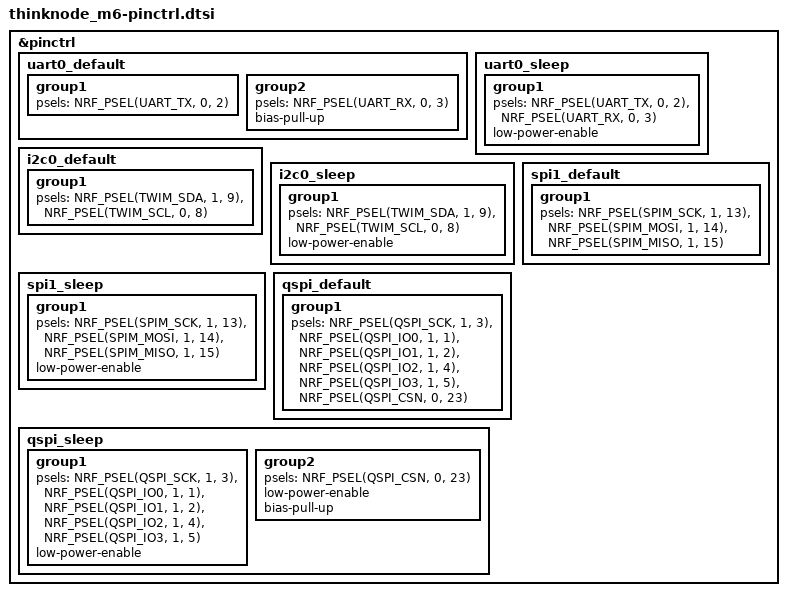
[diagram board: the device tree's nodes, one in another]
/*
 * Elecrow ThinkNode M6 - Pin Control
 * Copyright (c) 2025 ZephCore
 * SPDX-License-Identifier: MIT
 *
 * Pin assignments from Arduino variant.h and platformio.ini:
 * - SPI1 (LoRa SX1262):  SCK=P1.13, MOSI=P1.14, MISO=P1.15, NSS=P1.12
 * - I2C0 (sensors):       SDA=P1.09, SCL=P0.08
 * - UART0 (GPS 9600):     TX=P0.02 (→GPS RX), RX=P0.03 (←GPS TX)
 * - QSPI (MX25R1635F):    SCK=P1.03, CS=P0.23, IO0=P1.01, IO1=P1.02,
 *                          IO2=P1.04, IO3=P1.05
 */

&pinctrl {
	/* GPS UART0 - 9600 baud
	 * Note: PIN_GPS_TX/RX naming is from GPS module's perspective in variant.h.
	 * nRF UART TX → P0.02 (PIN_GPS_RX), nRF UART RX ← P0.03 (PIN_GPS_TX). */
	uart0_default: uart0_default {
		group1 {
			psels = <NRF_PSEL(UART_TX, 0, 2)>;
		};
		group2 {
			psels = <NRF_PSEL(UART_RX, 0, 3)>;
			bias-pull-up;
		};
	};

	uart0_sleep: uart0_sleep {
		group1 {
			psels = <NRF_PSEL(UART_TX, 0, 2)>,
			        <NRF_PSEL(UART_RX, 0, 3)>;
			low-power-enable;
		};
	};

	/* I2C0 for on-board sensors */
	i2c0_default: i2c0_default {
		group1 {
			psels = <NRF_PSEL(TWIM_SDA, 1, 9)>,
			        <NRF_PSEL(TWIM_SCL, 0, 8)>;
		};
	};

	i2c0_sleep: i2c0_sleep {
		group1 {
			psels = <NRF_PSEL(TWIM_SDA, 1, 9)>,
			        <NRF_PSEL(TWIM_SCL, 0, 8)>;
			low-power-enable;
		};
	};

	/* SPI1 for SX1262 LoRa - CS controlled manually (P1.12) */
	spi1_default: spi1_default {
		group1 {
			psels = <NRF_PSEL(SPIM_SCK,  1, 13)>,
			        <NRF_PSEL(SPIM_MOSI, 1, 14)>,
			        <NRF_PSEL(SPIM_MISO, 1, 15)>;
		};
	};

	spi1_sleep: spi1_sleep {
		group1 {
			psels = <NRF_PSEL(SPIM_SCK,  1, 13)>,
			        <NRF_PSEL(SPIM_MOSI, 1, 14)>,
			        <NRF_PSEL(SPIM_MISO, 1, 15)>;
			low-power-enable;
		};
	};

	/* QSPI for MX25R1635F 2MB external flash */
	qspi_default: qspi_default {
		group1 {
			psels = <NRF_PSEL(QSPI_SCK, 1, 3)>,
			        <NRF_PSEL(QSPI_IO0, 1, 1)>,
			        <NRF_PSEL(QSPI_IO1, 1, 2)>,
			        <NRF_PSEL(QSPI_IO2, 1, 4)>,
			        <NRF_PSEL(QSPI_IO3, 1, 5)>,
			        <NRF_PSEL(QSPI_CSN, 0, 23)>;
		};
	};

	qspi_sleep: qspi_sleep {
		group1 {
			psels = <NRF_PSEL(QSPI_SCK, 1, 3)>,
			        <NRF_PSEL(QSPI_IO0, 1, 1)>,
			        <NRF_PSEL(QSPI_IO1, 1, 2)>,
			        <NRF_PSEL(QSPI_IO2, 1, 4)>,
			        <NRF_PSEL(QSPI_IO3, 1, 5)>;
			low-power-enable;
		};
		group2 {
			psels = <NRF_PSEL(QSPI_CSN, 0, 23)>;
			low-power-enable;
			bias-pull-up;
		};
	};
};
